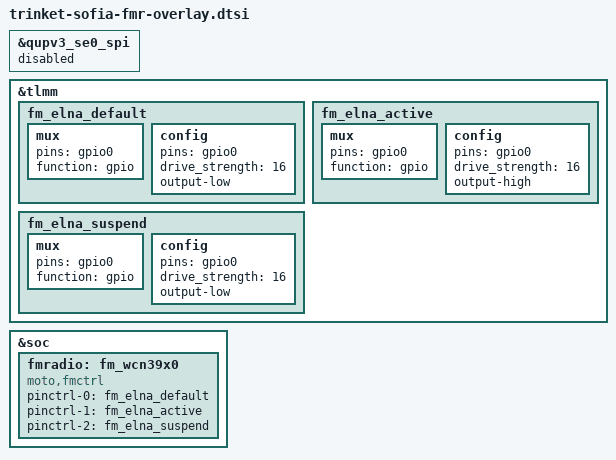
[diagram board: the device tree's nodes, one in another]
&qupv3_se0_spi {
	status = "disabled";
};

&tlmm {
	fm_elna_default: fm_elna_default {
		mux {
				pins = "gpio0";
				function = "gpio";
		};
		config {
				pins = "gpio0";
				drive_strength = <16>;
				output-low;
		};
	};

	fm_elna_active: fm_elna_active {
		mux {
				pins = "gpio0";
				function = "gpio";
		};
		config {
				pins = "gpio0";
				drive_strength = <16>;
				output-high;
		};
	};

	fm_elna_suspend: fm_elna_suspend {
		mux {
				pins = "gpio0";
				function = "gpio";
		};
		config {
				pins = "gpio0";
				drive_strength = <16>;
				output-low;
		};
	};
};

&soc {
	fmradio: fm_wcn39x0 {
		status = "ok";
		compatible = "moto,fmctrl";
		pinctrl-names = "default", "elna_active", "elna_suspend";
		pinctrl-0 = <&fm_elna_default>;
		pinctrl-1 = <&fm_elna_active>;
		pinctrl-2 = <&fm_elna_suspend>;
	};
};

